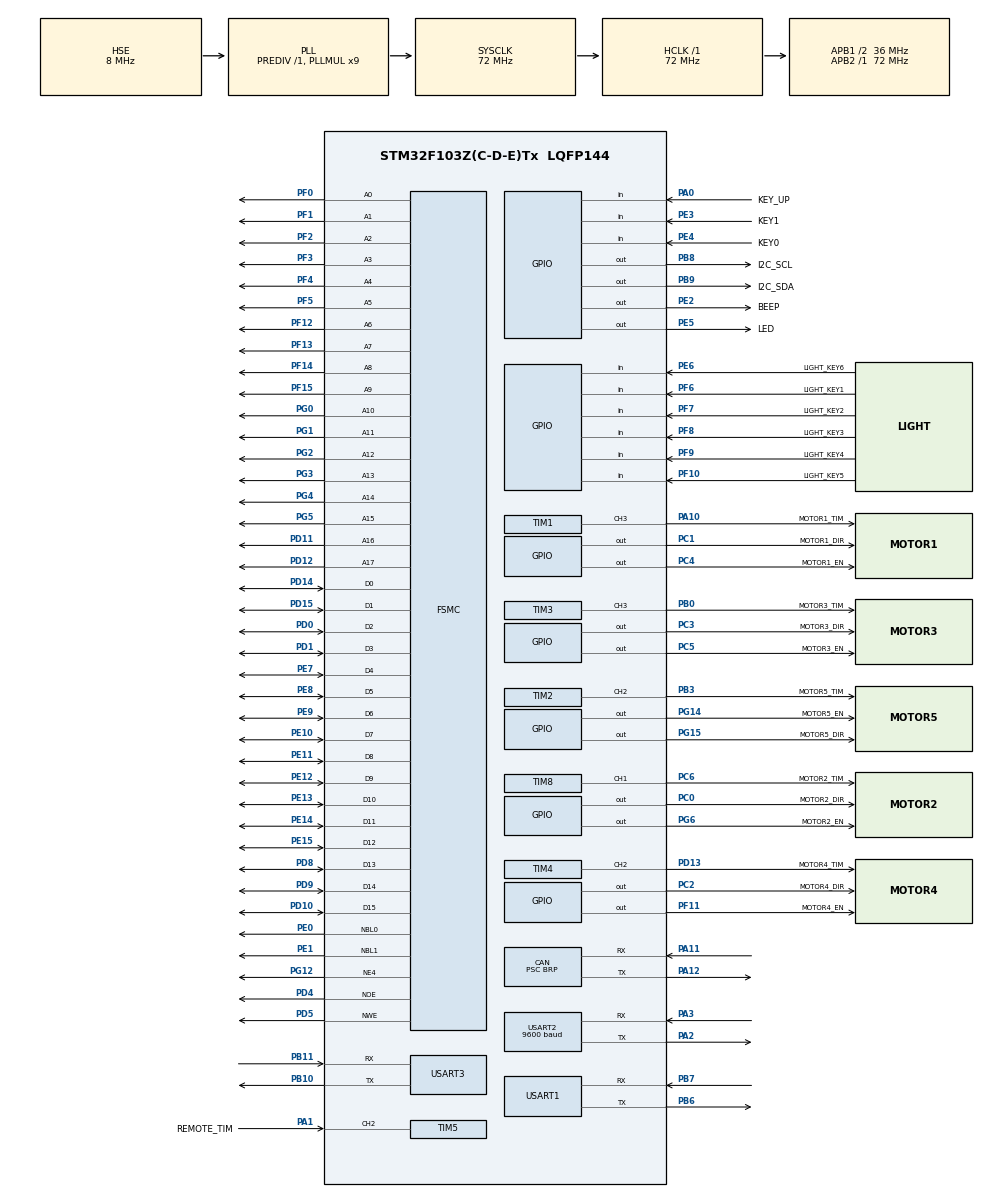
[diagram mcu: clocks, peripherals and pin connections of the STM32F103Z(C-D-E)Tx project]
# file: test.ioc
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CAN.BS1=CAN_BS1_9TQ
CAN.BS2=CAN_BS2_8TQ
CAN.CalculateBaudRate=500000
CAN.CalculateTimeBit=2000
CAN.CalculateTimeQuantum=111.11111111111111
CAN.Prescaler=BRP
Dma.Request0=USART3_RX
Dma.USART3_RX.0.Direction=DMA_PERIPH_TO_MEMORY
Dma.USART3_RX.0.Instance=DMA1_Channel3
Dma.USART3_RX.0.MemDataAlignment=DMA_MDATAALIGN_BYTE
Dma.USART3_RX.0.MemInc=DMA_MINC_ENABLE
Dma.USART3_RX.0.Mode=DMA_NORMAL
Dma.USART3_RX.0.PeriphDataAlignment=DMA_PDATAALIGN_BYTE
Dma.USART3_RX.0.PeriphInc=DMA_PINC_DISABLE
Dma.USART3_RX.0.Priority=DMA_PRIORITY_LOW
FSMC.AddressSetupTime1=0x0
FSMC.BusTurnAroundDuration1=0x0
FSMC.DataSetupTime1=0x3
FSMC.WriteOperation1=FSMC_WRITE_OPERATION_ENABLE
Mcu.Family=STM32F1
Mcu.Name=STM32F103Z(C-D-E)Tx
Mcu.Package=LQFP144
Mcu.UserConstants=PSC,18-1;ARR,0xFFFF - 1;USMART_ARR,1000;USMART_PSC,72 * 100 - 1;BRP,4
NVIC.DMA1_Channel3_IRQn=true\:0\:0\:false\:false\:true\:false\:true\:true
NVIC.PriorityGroup=NVIC_PRIORITYGROUP_4
NVIC.TIM1_CC_IRQn=true\:2\:0\:true\:false\:true\:true\:true\:true
NVIC.TIM2_IRQn=true\:2\:0\:true\:false\:true\:true\:true\:true
NVIC.TIM3_IRQn=true\:2\:0\:true\:false\:true\:true\:true\:true
NVIC.TIM4_IRQn=true\:2\:0\:true\:false\:true\:true\:true\:true
NVIC.TIM5_IRQn=true\:1\:0\:true\:false\:true\:true\:true\:true
NVIC.TIM8_CC_IRQn=true\:2\:0\:true\:false\:true\:true\:true\:true
NVIC.USART1_IRQn=true\:3\:0\:true\:false\:true\:true\:true\:true
NVIC.USART2_IRQn=true\:0\:0\:false\:false\:true\:true\:true\:true
NVIC.USART3_IRQn=true\:0\:0\:false\:false\:true\:true\:true\:true
NVIC.USB_LP_CAN1_RX0_IRQn=true\:0\:0\:false\:false\:true\:true\:true\:true
OSC_IN.Mode=HSE-External-Oscillator
OSC_IN.Signal=RCC_OSC_IN
OSC_OUT.Mode=HSE-External-Oscillator
OSC_OUT.Signal=RCC_OSC_OUT
PA0-WKUP.GPIO_Label=KEY_UP
PA0-WKUP.GPIO_PuPd=GPIO_PULLDOWN
PA0-WKUP.Signal=GPIO_Input
PA1.GPIO_Label=REMOTE_TIM
PA1.Signal=S_TIM5_CH2
PA10.GPIO_Label=MOTOR1_TIM
PA10.GPIO_Speed=GPIO_SPEED_FREQ_HIGH
PA10.Signal=S_TIM1_CH3
PA11.Mode=CAN_Activate
PA11.Signal=CAN_RX
PA12.Mode=CAN_Activate
PA12.Signal=CAN_TX
PA13.Mode=Serial_Wire
PA13.Signal=SYS_JTMS-SWDIO
PA14.Mode=Serial_Wire
PA14.Signal=SYS_JTCK-SWCLK
PA2.Mode=Asynchronous
PA2.Signal=USART2_TX
PA3.Mode=Asynchronous
PA3.Signal=USART2_RX
PB0.GPIO_Label=MOTOR3_TIM
PB0.GPIO_Speed=GPIO_SPEED_FREQ_HIGH
PB0.Signal=S_TIM3_CH3
PB10.Mode=Asynchronous
PB10.Signal=USART3_TX
PB11.Mode=Asynchronous
PB11.Signal=USART3_RX
PB3.GPIO_Label=MOTOR5_TIM
PB3.GPIO_Speed=GPIO_SPEED_FREQ_HIGH
PB3.Signal=S_TIM2_CH2
PB6.Mode=Asynchronous
PB6.Signal=USART1_TX
PB7.Mode=Asynchronous
PB7.Signal=USART1_RX
PB8.GPIO_Label=I2C_SCL
PB8.GPIO_PuPd=GPIO_PULLUP
PB8.GPIO_Speed=GPIO_SPEED_FREQ_HIGH
PB8.PinState=GPIO_PIN_RESET
PB8.Signal=GPIO_Output
PB9.GPIO_Label=I2C_SDA
PB9.GPIO_ModeDefaultOutputPP=GPIO_MODE_OUTPUT_OD
PB9.GPIO_PuPd=GPIO_NOPULL
PB9.GPIO_Speed=GPIO_SPEED_FREQ_HIGH
PB9.PinState=GPIO_PIN_SET
PB9.Signal=GPIO_Output
PC0.GPIO_Label=MOTOR2_DIR
PC0.GPIO_Speed=GPIO_SPEED_FREQ_LOW
PC0.PinState=GPIO_PIN_SET
PC0.Signal=GPIO_Output
PC1.GPIO_Label=MOTOR1_DIR
PC1.PinState=GPIO_PIN_SET
PC1.Signal=GPIO_Output
PC2.GPIO_Label=MOTOR4_DIR
PC2.PinState=GPIO_PIN_SET
PC2.Signal=GPIO_Output
PC3.GPIO_Label=MOTOR3_DIR
PC3.PinState=GPIO_PIN_SET
PC3.Signal=GPIO_Output
PC4.GPIO_Label=MOTOR1_EN
PC4.Signal=GPIO_Output
PC5.GPIO_Label=MOTOR3_EN
PC5.PinState=GPIO_PIN_RESET
PC5.Signal=GPIO_Output
PC6.GPIO_Label=MOTOR2_TIM
PC6.GPIO_Speed=GPIO_SPEED_FREQ_HIGH
PC6.Signal=S_TIM8_CH1
PD0.Signal=FSMC_D2_DA2
PD1.Signal=FSMC_D3_DA3
PD10.Signal=FSMC_D15_DA15
PD11.Signal=FSMC_A16_CLE
PD12.Signal=FSMC_A17_ALE
PD13.GPIO_Label=MOTOR4_TIM
PD13.GPIO_Speed=GPIO_SPEED_FREQ_HIGH
PD13.Signal=S_TIM4_CH2
PD14.Signal=FSMC_D0_DA0
PD15.Signal=FSMC_D1_DA1
PD4.Signal=FSMC_NOE
PD5.Signal=FSMC_NWE
PD8.Signal=FSMC_D13_DA13
PD9.Signal=FSMC_D14_DA14
PE0.Signal=FSMC_NBL0
PE1.Signal=FSMC_NBL1
PE10.Signal=FSMC_D7_DA7
PE11.Signal=FSMC_D8_DA8
PE12.Signal=FSMC_D9_DA9
PE13.Signal=FSMC_D10_DA10
PE14.Signal=FSMC_D11_DA11
PE15.Signal=FSMC_D12_DA12
PE2.GPIO_Label=BEEP
PE2.GPIO_PuPd=GPIO_PULLDOWN
PE2.Signal=GPIO_Output
PE3.GPIO_Label=KEY1
PE3.GPIO_PuPd=GPIO_PULLDOWN
PE3.Signal=GPIO_Input
PE4.GPIO_Label=KEY0
PE4.GPIO_PuPd=GPIO_PULLDOWN
PE4.Signal=GPIO_Input
PE5.GPIO_Label=LED
PE5.GPIO_PuPd=GPIO_PULLUP
PE5.PinState=GPIO_PIN_SET
PE5.Signal=GPIO_Output
PE6.GPIO_Label=LIGHT_KEY6
PE6.Signal=GPIO_Input
PE7.Signal=FSMC_D4_DA4
PE8.Signal=FSMC_D5_DA5
PE9.Signal=FSMC_D6_DA6
PF0.Signal=FSMC_A0
PF1.Signal=FSMC_A1
PF10.GPIO_Label=LIGHT_KEY5
PF10.Signal=GPIO_Input
PF11.GPIO_Label=MOTOR4_EN
PF11.Signal=GPIO_Output
PF12.Signal=FSMC_A6
PF13.Signal=FSMC_A7
PF14.Signal=FSMC_A8
PF15.Signal=FSMC_A9
PF2.Signal=FSMC_A2
PF3.Signal=FSMC_A3
PF4.Signal=FSMC_A4
PF5.Signal=FSMC_A5
PF6.GPIO_Label=LIGHT_KEY1
PF6.Signal=GPIO_Input
PF7.GPIO_Label=LIGHT_KEY2
PF7.Signal=GPIO_Input
PF8.GPIO_Label=LIGHT_KEY3
PF8.Signal=GPIO_Input
PF9.GPIO_Label=LIGHT_KEY4
PF9.Signal=GPIO_Input
PG0.Signal=FSMC_A10
PG1.Signal=FSMC_A11
PG12.Mode=NorPsramChipSelect4_1
PG12.Signal=FSMC_NE4
PG14.GPIO_Label=MOTOR5_EN
PG14.Signal=GPIO_Output
PG15.GPIO_Label=MOTOR5_DIR
PG15.PinState=GPIO_PIN_SET
PG15.Signal=GPIO_Output
PG2.Signal=FSMC_A12
PG3.Signal=FSMC_A13
PG4.Signal=FSMC_A14
PG5.Signal=FSMC_A15
PG6.GPIO_Label=MOTOR2_EN
PG6.Signal=GPIO_Output
ProjectManager.HeapSize=0x200
ProjectManager.StackSize=0x400
ProjectManager.TargetToolchain=MDK-ARM V5.32
RCC.AHBFreq_Value=72000000
RCC.APB1CLKDivider=RCC_HCLK_DIV2
RCC.APB1Freq_Value=36000000
RCC.APB1TimFreq_Value=72000000
RCC.APB2Freq_Value=72000000
RCC.APB2TimFreq_Value=72000000
RCC.HCLKFreq_Value=72000000
RCC.PLLMUL=RCC_PLL_MUL9
RCC.PLLSourceVirtual=RCC_PLLSOURCE_HSE
RCC.RTCClockSelection=RCC_RTCCLKSOURCE_LSE
RCC.SYSCLKFreq_VALUE=72000000
RCC.SYSCLKSource=RCC_SYSCLKSOURCE_PLLCLK
RCC.USBFreq_Value=72000000
SH.FSMC_A0.0=FSMC_A0,18b-a1
SH.FSMC_A1.0=FSMC_A1,18b-a1
SH.FSMC_A10.0=FSMC_A10,18b-a1
SH.FSMC_A11.0=FSMC_A11,18b-a1
SH.FSMC_A12.0=FSMC_A12,18b-a1
SH.FSMC_A13.0=FSMC_A13,18b-a1
SH.FSMC_A14.0=FSMC_A14,18b-a1
SH.FSMC_A15.0=FSMC_A15,18b-a1
SH.FSMC_A16_CLE.0=FSMC_A16,18b-a1
SH.FSMC_A17_ALE.0=FSMC_A17,18b-a1
SH.FSMC_A2.0=FSMC_A2,18b-a1
SH.FSMC_A3.0=FSMC_A3,18b-a1
SH.FSMC_A4.0=FSMC_A4,18b-a1
SH.FSMC_A5.0=FSMC_A5,18b-a1
SH.FSMC_A6.0=FSMC_A6,18b-a1
SH.FSMC_A7.0=FSMC_A7,18b-a1
SH.FSMC_A8.0=FSMC_A8,18b-a1
SH.FSMC_A9.0=FSMC_A9,18b-a1
SH.FSMC_D0_DA0.0=FSMC_D0,16b-d1
SH.FSMC_D10_DA10.0=FSMC_D10,16b-d1
SH.FSMC_D11_DA11.0=FSMC_D11,16b-d1
SH.FSMC_D12_DA12.0=FSMC_D12,16b-d1
SH.FSMC_D13_DA13.0=FSMC_D13,16b-d1
SH.FSMC_D14_DA14.0=FSMC_D14,16b-d1
SH.FSMC_D15_DA15.0=FSMC_D15,16b-d1
SH.FSMC_D1_DA1.0=FSMC_D1,16b-d1
SH.FSMC_D2_DA2.0=FSMC_D2,16b-d1
SH.FSMC_D3_DA3.0=FSMC_D3,16b-d1
SH.FSMC_D4_DA4.0=FSMC_D4,16b-d1
SH.FSMC_D5_DA5.0=FSMC_D5,16b-d1
SH.FSMC_D6_DA6.0=FSMC_D6,16b-d1
SH.FSMC_D7_DA7.0=FSMC_D7,16b-d1
SH.FSMC_D8_DA8.0=FSMC_D8,16b-d1
SH.FSMC_D9_DA9.0=FSMC_D9,16b-d1
SH.FSMC_NBL0.0=FSMC_NBL0,2ByteEnable1
SH.FSMC_NBL1.0=FSMC_NBL1,2ByteEnable1
SH.FSMC_NOE.0=FSMC_NOE,Sram1
SH.FSMC_NWE.0=FSMC_NWE,Sram1
SH.S_TIM1_CH3.0=TIM1_CH3,Output Compare3 CH3
SH.S_TIM2_CH2.0=TIM2_CH2,Output Compare2 CH2
SH.S_TIM3_CH3.0=TIM3_CH3,Output Compare3 CH3
SH.S_TIM4_CH2.0=TIM4_CH2,Output Compare2 CH2
SH.S_TIM5_CH2.0=TIM5_CH2,Input_Capture2_from_TI2
SH.S_TIM8_CH1.0=TIM8_CH1,Output Compare1 CH1
TIM1.Channel-Output\ Compare3\ CH3=TIM_CHANNEL_3
TIM1.OCMode_3=TIM_OCMODE_TOGGLE
TIM1.Period=ARR
TIM1.Prescaler=PSC
TIM1.Pulse-Output\ Compare3\ CH3=0
TIM2.Channel-Output\ Compare2\ CH2=TIM_CHANNEL_2
TIM2.OCMode_2=TIM_OCMODE_TOGGLE
TIM2.Period=ARR
TIM2.Prescaler=PSC
TIM3.Channel-Output\ Compare3\ CH3=TIM_CHANNEL_3
TIM3.OCMode_3=TIM_OCMODE_TOGGLE
TIM3.Period=ARR
TIM3.Prescaler=PSC
TIM4.Channel-Output\ Compare2\ CH2=TIM_CHANNEL_2
TIM4.OCMode_2=TIM_OCMODE_TOGGLE
TIM4.Period=ARR
TIM4.Prescaler=PSC
TIM5.Channel-Input_Capture2_from_TI2=TIM_CHANNEL_2
TIM5.ICFilter_CH2=0x03
TIM5.Period=10000
TIM5.Prescaler=72-1
TIM6.Period=10000 - 1
TIM6.Prescaler=72 - 1
TIM8.Channel-Output\ Compare1\ CH1=TIM_CHANNEL_1
TIM8.OCMode_1=TIM_OCMODE_TOGGLE
TIM8.Period=ARR
TIM8.Prescaler=PSC
USART1.VirtualMode=VM_ASYNC
USART2.BaudRate=9600
USART2.VirtualMode=VM_ASYNC
USART3.VirtualMode=VM_ASYNC
VP_TIM6_VS_ClockSourceINT.Mode=Enable_Timer
board=custom

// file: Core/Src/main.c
/* USER CODE BEGIN Header */
/**
 ******************************************************************************
 * @file           : main.c
 * @brief          : Main program body
 ******************************************************************************
 * @attention
 *
 * Copyright (c) 2024 STMicroelectronics.
 * All rights reserved.
 *
 * This software is licensed under terms that can be found in the LICENSE file
 * in the root directory of this software component.
 * If no LICENSE file comes with this software, it is provided AS-IS.
 *
 ******************************************************************************
 */
/* USER CODE END Header */
#include "main.h"
#include "can.h"
#include "dma.h"
#include "tim.h"
#include "usart.h"
#include "gpio.h"
#include "fsmc.h"

/* USER CODE BEGIN Includes */
#include "../../User/BSP/Beep/Beep.h"
#include "../../User/BSP/Led/Led.h"
#include "../../User/BSP/Key/Key.h"
#include "../../User/BSP/EEPROM/EEPROM.h"
#include "../../User/BSP/Remote/Remote.h"
#include "../../User/APP/Menu/Menu.h"
#include "../../User/Tools/Delay/Delay.h"
#include "../../User/Tools/Tools/TOOLS.h"
#include "../../User/Tools/USMART/usmart.h"
#include "../../User/Control/ZDTmotorControl/ZDTmotorControl.h"
#include "../../User/Control/SteppingMotorControl/SteppingMotorControl.h"
#include "../../User/Manager/MsgManage/MsgManage.h"
#include "../../User/Manager/TimManage/TimManage.h"
/* USER CODE END Includes */

/* USER CODE BEGIN PV */
uint8_t key = 0;
uint8_t ledToggleTick = 0;
uint8_t tbuf[40];
char *str;
/* USER CODE END PV */

void SystemClock_Config(void);

int main(void)
{

  /* MCU Configuration--------------------------------------------------------*/

  /* Reset of all peripherals, Initializes the Flash interface and the Systick. */
  HAL_Init();

  /* Configure the system clock */
  SystemClock_Config();

  /* Initialize all configured peripherals */
  MX_GPIO_Init();
  MX_DMA_Init();
  MX_FSMC_Init();
  MX_TIM1_Init();
  MX_TIM2_Init();
  MX_TIM3_Init();
  MX_TIM4_Init();
  MX_TIM8_Init();
  MX_USART1_UART_Init();
  MX_USART2_UART_Init();
  MX_USART3_UART_Init();
  MX_CAN_Init();
  MX_TIM5_Init();
  MX_TIM6_Init();
  /* USER CODE BEGIN 2 */
  mallocInit();
  motorInit();
  usmart_dev.init(72);
  FormDataInit(&OpennMvData);
  beepBeep(getMemoryUsage(OUT));
  beepBeep(eepromTest());
  /* USER CODE END 2 */

  /* Infinite loop */
  while (1)
  {

    /* USER CODE BEGIN 3 */
    key = remoteScan();

        if (key)
        {
            switch (key)
            {
            case 69:
                str = "1    ";
                motorMoveFast(&motor1,100,400);
                break;
            case 70:
                str = "2    ";
                motorMoveFast(&motor1,100,-400);
                break;
            case 71:
                str = "3    ";
                motorMove(&motor2,800,1.5,1.5,3200);
                waitMotor(2);
                break;
            case 68:
                str = "4    ";
                motorMove(&motor2,800,1,1,-3200);
                waitMotor(2);
                break;
            case 64:
                str = "5    ";
                break;
            case 67:
                str = "6    ";
                break;
            case 7:
                str = "7    ";
                break;
            case 21:
                str = "8    ";
                break;
            case 9:
                str = "9    ";
                break;
            case 25:
                str = "0    ";
                break;
            case 13:
                str = "#    ";
                break;
            case 22:
                str = "*    ";
                break;
            case 24:
                str = "UP   ";
                break;
            case 82:
                str = "DOWM ";
                break;
            case 8:
                str = "LEFT ";
                break;
            case 90:
                str = "RIGHT";
                break;
            case 28:
                str = "OK   ";
                break;
            default:
                str = "NULL ";
                break;
            }
        }
        else
        {
            HAL_Delay(10);
        }

        ledToggleTick++;

        if (ledToggleTick == 50)
        {
            ledToggleTick = 0;
            lastSta = 0;
            LED_TOGGLE(); /* LED0闪烁 */
        }
  }
  /* USER CODE END 3 */
}

void SystemClock_Config(void)
{
  RCC_OscInitTypeDef RCC_OscInitStruct = {0};
  RCC_ClkInitTypeDef RCC_ClkInitStruct = {0};

  /** Initializes the RCC Oscillators according to the specified parameters
  * in the RCC_OscInitTypeDef structure.
  */
  RCC_OscInitStruct.OscillatorType = RCC_OSCILLATORTYPE_HSE;
  RCC_OscInitStruct.HSEState = RCC_HSE_ON;
  RCC_OscInitStruct.HSEPredivValue = RCC_HSE_PREDIV_DIV1;
  RCC_OscInitStruct.HSIState = RCC_HSI_ON;
  RCC_OscInitStruct.PLL.PLLState = RCC_PLL_ON;
  RCC_OscInitStruct.PLL.PLLSource = RCC_PLLSOURCE_HSE;
  RCC_OscInitStruct.PLL.PLLMUL = RCC_PLL_MUL9;
  if (HAL_RCC_OscConfig(&RCC_OscInitStruct) != HAL_OK)
  {
    Error_Handler();
  }

  /** Initializes the CPU, AHB and APB buses clocks
  */
  RCC_ClkInitStruct.ClockType = RCC_CLOCKTYPE_HCLK|RCC_CLOCKTYPE_SYSCLK
                              |RCC_CLOCKTYPE_PCLK1|RCC_CLOCKTYPE_PCLK2;
  RCC_ClkInitStruct.SYSCLKSource = RCC_SYSCLKSOURCE_PLLCLK;
  RCC_ClkInitStruct.AHBCLKDivider = RCC_SYSCLK_DIV1;
  RCC_ClkInitStruct.APB1CLKDivider = RCC_HCLK_DIV2;
  RCC_ClkInitStruct.APB2CLKDivider = RCC_HCLK_DIV1;

  if (HAL_RCC_ClockConfig(&RCC_ClkInitStruct, FLASH_LATENCY_2) != HAL_OK)
  {
    Error_Handler();
  }
}

void Error_Handler(void)
{
  __disable_irq();
  while (1)
  {
  }
}
